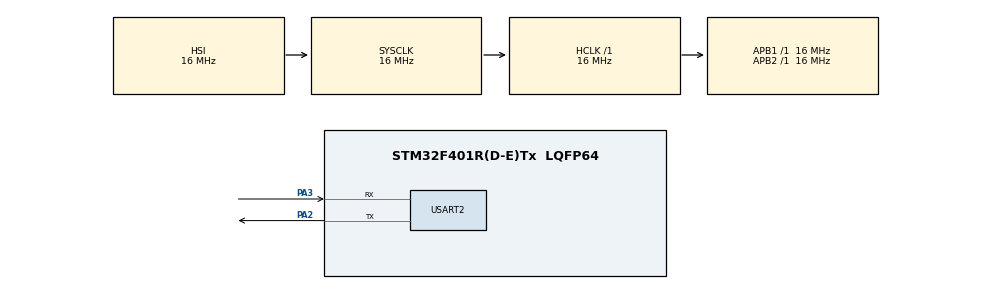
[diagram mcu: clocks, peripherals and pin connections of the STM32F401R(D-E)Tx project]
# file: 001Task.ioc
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FREERTOS.Tasks01=defaultTask,24,128,StartDefaultTask,Default,NULL,Dynamic,NULL,NULL
FREERTOS.configUSE_NEWLIB_REENTRANT=1
Mcu.Family=STM32F4
Mcu.Name=STM32F401R(D-E)Tx
Mcu.Package=LQFP64
NVIC.PriorityGroup=NVIC_PRIORITYGROUP_4
NVIC.TIM5_IRQn=true\:15\:0\:false\:false\:true\:false\:false\:true\:true
NVIC.TimeBase=TIM5_IRQn
NVIC.TimeBaseIP=TIM5
PA2.Mode=Asynchronous
PA2.Signal=USART2_TX
PA3.Mode=Asynchronous
PA3.Signal=USART2_RX
ProjectManager.HeapSize=0x200
ProjectManager.StackSize=0x400
ProjectManager.TargetToolchain=STM32CubeIDE
RCC.AHBFreq_Value=16000000
RCC.APB1Freq_Value=16000000
RCC.APB2Freq_Value=16000000
RCC.CortexFreq_Value=16000000
RCC.HSE_VALUE=25000000
RCC.HSI_VALUE=16000000
RCC.LSE_VALUE=32768
RCC.SYSCLKFreq_VALUE=16000000
RCC.VCOOutputFreq_Value=192000000
USART2.VirtualMode=VM_ASYNC
VP_FREERTOS_VS_CMSIS_V2.Mode=CMSIS_V2
VP_SYS_VS_tim5.Mode=TIM5
board=custom

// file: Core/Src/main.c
/* USER CODE BEGIN Header */
/**
  ******************************************************************************
  * @file           : main.c
  * @brief          : Main program body
  ******************************************************************************
  * @attention
  *
  * Copyright (c) 2026 STMicroelectronics.
  * All rights reserved.
  *
  * This software is licensed under terms that can be found in the LICENSE file
  * in the root directory of this software component.
  * If no LICENSE file comes with this software, it is provided AS-IS.
  *
  ******************************************************************************
  */
/* USER CODE END Header */
#include "main.h"
#include "cmsis_os.h"

/* USER CODE BEGIN Includes */
#include<stdio.h>
#include "FreeRTOS.h"
#include "task.h"
#include "SEGGER_SYSVIEW.h"
#include <string.h>

/* USER CODE END Includes */
void SEGGER_UART_init(U32 baud);

UART_HandleTypeDef huart2;

/* Definitions for defaultTask */
osThreadId_t defaultTaskHandle;
const osThreadAttr_t defaultTask_attributes = {
  .name = "defaultTask",
  .stack_size = 128 * 4,
  .priority = (osPriority_t) osPriorityNormal,
};
/* USER CODE BEGIN PV */
#define DEMCR      (*(volatile uint32_t*)0xE000EDFC)
#define DWT_CTRL   (*(volatile uint32_t*)0xE0001000)
#define DWT_CYCCNT (*(volatile uint32_t*)0xE0001004)
/* USER CODE END PV */

void SystemClock_Config(void);
static void MX_GPIO_Init(void);
static void MX_USART2_UART_Init(void);
void StartDefaultTask(void *argument);

/* USER CODE BEGIN PFP */
static void task1_handler(void* parameters);
static void task2_handler(void* parameters);

/* USER CODE END PFP */

int main(void)
{

  /* USER CODE BEGIN 1 */
TaskHandle_t task1_handle;
TaskHandle_t task2_handle;

BaseType_t Status;
  /* USER CODE END 1 */

  /* MCU Configuration--------------------------------------------------------*/

  /* Reset of all peripherals, Initializes the Flash interface and the Systick. */
  HAL_Init();

  /* Configure the system clock */
  SystemClock_Config();

  /* Initialize all configured peripherals */
  MX_GPIO_Init();
  MX_USART2_UART_Init();
  /* USER CODE BEGIN 2 */

  //Enable the CYCCNT counter.
  /* USER CODE BEGIN 2 */

  // Enable the CYCCNT counter
  DEMCR |= (1 << 24);      // Enable trace
  DWT_CYCCNT = 0;          // Reset cycle counter
  DWT_CTRL |= (1 << 0);    // Enable CYCCNT

  SEGGER_SYSVIEW_Conf();

  SEGGER_SYSVIEW_Start();

  Status = xTaskCreate(task1_handler,
                       "Task-1",
                       200,
                       "Hello World From Task-1",
                       2,
                       &task1_handle);

  configASSERT(Status == pdPASS);

  Status = xTaskCreate(task2_handler,
                       "Task-2",
                       200,
                       "Hello World From Task-2",
                       2,
                       &task2_handle);

  configASSERT(Status == pdPASS);

  // Start the FreeRTOS scheduler
  vTaskStartScheduler();
  //if the control comes  herey then the launch of the scheduler has failed due to
  //insufficient memory in heap
  /* USER CODE END 2 */

  /* Init scheduler */
  //osKernelInitialize();

  /* Create the thread(s) */
  /* creation of defaultTask */
  //defaultTaskHandle = osThreadNew(StartDefaultTask, NULL, &defaultTask_attributes);

  /* Start scheduler */
  //osKernelStart();

  /* We should never get here as control is now taken by the scheduler */

  /* Infinite loop */
  /* USER CODE BEGIN WHILE */
  //while (1)
 // {
    /* USER CODE END WHILE */

    /* USER CODE BEGIN 3 */
  //}
  /* USER CODE END 3 */
}

void SystemClock_Config(void)
{
  RCC_OscInitTypeDef RCC_OscInitStruct = {0};
  RCC_ClkInitTypeDef RCC_ClkInitStruct = {0};

  /** Configure the main internal regulator output voltage
  */
  __HAL_RCC_PWR_CLK_ENABLE();
  __HAL_PWR_VOLTAGESCALING_CONFIG(PWR_REGULATOR_VOLTAGE_SCALE2);

  /** Initializes the RCC Oscillators according to the specified parameters
  * in the RCC_OscInitTypeDef structure.
  */
  RCC_OscInitStruct.OscillatorType = RCC_OSCILLATORTYPE_HSI;
  RCC_OscInitStruct.HSIState = RCC_HSI_ON;
  RCC_OscInitStruct.HSICalibrationValue = RCC_HSICALIBRATION_DEFAULT;
  RCC_OscInitStruct.PLL.PLLState = RCC_PLL_NONE;
  if (HAL_RCC_OscConfig(&RCC_OscInitStruct) != HAL_OK)
  {
    Error_Handler();
  }

  /** Initializes the CPU, AHB and APB buses clocks
  */
  RCC_ClkInitStruct.ClockType = RCC_CLOCKTYPE_HCLK|RCC_CLOCKTYPE_SYSCLK
                              |RCC_CLOCKTYPE_PCLK1|RCC_CLOCKTYPE_PCLK2;
  RCC_ClkInitStruct.SYSCLKSource = RCC_SYSCLKSOURCE_HSI;
  RCC_ClkInitStruct.AHBCLKDivider = RCC_SYSCLK_DIV1;
  RCC_ClkInitStruct.APB1CLKDivider = RCC_HCLK_DIV1;
  RCC_ClkInitStruct.APB2CLKDivider = RCC_HCLK_DIV1;

  if (HAL_RCC_ClockConfig(&RCC_ClkInitStruct, FLASH_LATENCY_0) != HAL_OK)
  {
    Error_Handler();
  }
}

static void MX_USART2_UART_Init(void)
{

  huart2.Instance = USART2;
  huart2.Init.BaudRate = 115200;
  huart2.Init.WordLength = UART_WORDLENGTH_8B;
  huart2.Init.StopBits = UART_STOPBITS_1;
  huart2.Init.Parity = UART_PARITY_NONE;
  huart2.Init.Mode = UART_MODE_TX_RX;
  huart2.Init.HwFlowCtl = UART_HWCONTROL_NONE;
  huart2.Init.OverSampling = UART_OVERSAMPLING_16;
  if (HAL_UART_Init(&huart2) != HAL_OK)
  {
    Error_Handler();
  }

}

static void MX_GPIO_Init(void)
{

  /* GPIO Ports Clock Enable */
  __HAL_RCC_GPIOA_CLK_ENABLE();

}

/* USER CODE BEGIN 4 */
static void task1_handler(void* parameters)
{
    char msg[100];

    while(1)
    {
        snprintf(msg, 100, "%s\n", (char*)parameters);
        SEGGER_SYSVIEW_PrintfTarget( msg);
        taskYIELD();
    }
}

static void task2_handler(void* parameters)
{
    char msg[100];

    while(1)
    {
        snprintf(msg, 100, "%s\n", (char*)parameters);
        SEGGER_SYSVIEW_PrintfTarget( msg);
        taskYIELD();
    }
}
/* USER CODE END 4 */

void StartDefaultTask(void *argument)
{
  for(;;)
  {
    osDelay(1);
  }
}

void HAL_TIM_PeriodElapsedCallback(TIM_HandleTypeDef *htim)
{
  if (htim->Instance == TIM5)
  {
    HAL_IncTick();
  }
}

void Error_Handler(void)
{
  __disable_irq();
  while (1)
  {
  }
}
